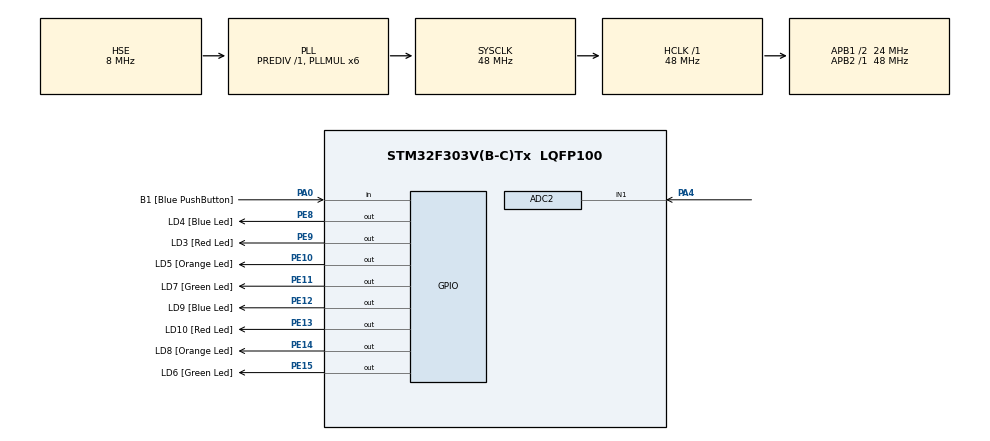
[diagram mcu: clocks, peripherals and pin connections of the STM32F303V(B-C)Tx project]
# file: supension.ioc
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ADC2.Channel-0\#ChannelRegularConversion=ADC_CHANNEL_1
ADC2.ContinuousConvMode=ENABLE
ADC2.DMAContinuousRequests=DISABLE
ADC2.InjNumberOfConversion=0
ADC2.NbrOfConversionFlag=1
ADC2.Offset-0\#ChannelRegularConversion=0
ADC2.OffsetNumber-0\#ChannelRegularConversion=ADC_OFFSET_NONE
ADC2.Rank-0\#ChannelRegularConversion=1
ADC2.SamplingTime-0\#ChannelRegularConversion=ADC_SAMPLETIME_1CYCLE_5
Dma.ADC2.0.Direction=DMA_PERIPH_TO_MEMORY
Dma.ADC2.0.Instance=DMA2_Channel1
Dma.ADC2.0.MemDataAlignment=DMA_MDATAALIGN_WORD
Dma.ADC2.0.MemInc=DMA_MINC_ENABLE
Dma.ADC2.0.Mode=DMA_CIRCULAR
Dma.ADC2.0.PeriphDataAlignment=DMA_PDATAALIGN_WORD
Dma.ADC2.0.PeriphInc=DMA_PINC_DISABLE
Dma.ADC2.0.Priority=DMA_PRIORITY_LOW
Dma.Request0=ADC2
Mcu.Family=STM32F3
Mcu.Name=STM32F303V(B-C)Tx
Mcu.Package=LQFP100
NVIC.DMA2_Channel1_IRQn=true\:0\:0\:false\:false\:true\:false\:true
NVIC.PriorityGroup=NVIC_PRIORITYGROUP_0
PA0.GPIO_Label=B1 [Blue PushButton]
PA0.Signal=GPIO_Input
PA4.Mode=IN1-Single-Ended
PA4.Signal=ADC2_IN1
PE10.GPIO_Label=LD5 [Orange Led]
PE10.Signal=GPIO_Output
PE11.GPIO_Label=LD7 [Green Led]
PE11.Signal=GPIO_Output
PE12.GPIO_Label=LD9 [Blue Led]
PE12.Signal=GPIO_Output
PE13.GPIO_Label=LD10 [Red Led]
PE13.Signal=GPIO_Output
PE14.GPIO_Label=LD8 [Orange Led]
PE14.Signal=GPIO_Output
PE15.GPIO_Label=LD6 [Green Led]
PE15.Signal=GPIO_Output
PE8.GPIO_Label=LD4 [Blue Led]
PE8.Signal=GPIO_Output
PE9.GPIO_Label=LD3 [Red Led]
PE9.Signal=GPIO_Output
PF0-OSC_IN.GPIO_Label=OSC_IN
PF0-OSC_IN.Mode=HSE-External-Oscillator
PF0-OSC_IN.Signal=RCC_OSC_IN
PF1-OSC_OUT.Mode=HSE-External-Oscillator
PF1-OSC_OUT.Signal=RCC_OSC_OUT
ProjectManager.HeapSize=0x200
ProjectManager.StackSize=0x400
ProjectManager.TargetToolchain=SW4STM32
RCC.AHBFreq_Value=48000000
RCC.APB1CLKDivider=RCC_HCLK_DIV2
RCC.APB1Freq_Value=24000000
RCC.APB1TimFreq_Value=48000000
RCC.APB2Freq_Value=48000000
RCC.APB2TimFreq_Value=48000000
RCC.CortexFreq_Value=48000000
RCC.HCLKFreq_Value=48000000
RCC.HSE_VALUE=8000000
RCC.HSI_VALUE=8000000
RCC.LSE_VALUE=32768
RCC.PLLMUL=RCC_PLL_MUL6
RCC.PLLSourceVirtual=RCC_PLLSOURCE_HSE
RCC.SYSCLKFreq_VALUE=48000000
RCC.SYSCLKSourceVirtual=RCC_SYSCLKSOURCE_PLLCLK
RCC.USBFreq_Value=48000000
board=STM32F3DISCOVERY

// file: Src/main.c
/* USER CODE BEGIN Header */
/**
  ******************************************************************************
  * @file           : main.c
  * @brief          : Main program body
  ******************************************************************************
  * @attention
  *
  * <h2><center>&copy; Copyright (c) 2019 STMicroelectronics.
  * All rights reserved.</center></h2>
  *
  * This software component is licensed by ST under BSD 3-Clause license,
  * the "License"; You may not use this file except in compliance with the
  * License. You may obtain a copy of the License at:
  *                        opensource.org/licenses/BSD-3-Clause
  *
  ******************************************************************************
  */
/* USER CODE END Header */

#include "main.h"
#include "adc.h"
#include "dma.h"
#include "gpio.h"

/* USER CODE BEGIN Includes */
#include <stdio.h>
/* USER CODE END Includes */

/* USER CODE BEGIN PTD */
volatile uint32_t acd_val;

double get_adc_flow() {
	return acd_val / (double) 4096.0;
}
/* USER CODE END PTD */

void SystemClock_Config(void);

int main(void)
{

  /* MCU Configuration--------------------------------------------------------*/

  /* Reset of all peripherals, Initializes the Flash interface and the Systick. */
  HAL_Init();

  /* Configure the system clock */
  SystemClock_Config();

  /* Initialize all configured peripherals */
  MX_GPIO_Init();
  MX_DMA_Init();
  MX_ADC2_Init();
  /* USER CODE BEGIN 2 */
  printf("OK!\n");
  HAL_ADC_Start_DMA(&hadc2, &acd_val, 1);
  /* USER CODE END 2 */

  /* Infinite loop */
  /* USER CODE BEGIN WHILE */
  while (1)
  {
	printf("%d\n", acd_val);
    HAL_GPIO_TogglePin(GPIOE, GPIO_PIN_9);
    HAL_Delay(500);
    /* USER CODE END WHILE */

  }
}

void SystemClock_Config(void)
{
  RCC_OscInitTypeDef RCC_OscInitStruct = {0};
  RCC_ClkInitTypeDef RCC_ClkInitStruct = {0};
  RCC_PeriphCLKInitTypeDef PeriphClkInit = {0};

  /** Initializes the CPU, AHB and APB busses clocks
  */
  RCC_OscInitStruct.OscillatorType = RCC_OSCILLATORTYPE_HSE;
  RCC_OscInitStruct.HSEState = RCC_HSE_ON;
  RCC_OscInitStruct.HSEPredivValue = RCC_HSE_PREDIV_DIV1;
  RCC_OscInitStruct.HSIState = RCC_HSI_ON;
  RCC_OscInitStruct.PLL.PLLState = RCC_PLL_ON;
  RCC_OscInitStruct.PLL.PLLSource = RCC_PLLSOURCE_HSE;
  RCC_OscInitStruct.PLL.PLLMUL = RCC_PLL_MUL6;
  if (HAL_RCC_OscConfig(&RCC_OscInitStruct) != HAL_OK)
  {
    Error_Handler();
  }
  /** Initializes the CPU, AHB and APB busses clocks
  */
  RCC_ClkInitStruct.ClockType = RCC_CLOCKTYPE_HCLK|RCC_CLOCKTYPE_SYSCLK
                              |RCC_CLOCKTYPE_PCLK1|RCC_CLOCKTYPE_PCLK2;
  RCC_ClkInitStruct.SYSCLKSource = RCC_SYSCLKSOURCE_PLLCLK;
  RCC_ClkInitStruct.AHBCLKDivider = RCC_SYSCLK_DIV1;
  RCC_ClkInitStruct.APB1CLKDivider = RCC_HCLK_DIV2;
  RCC_ClkInitStruct.APB2CLKDivider = RCC_HCLK_DIV1;

  if (HAL_RCC_ClockConfig(&RCC_ClkInitStruct, FLASH_LATENCY_1) != HAL_OK)
  {
    Error_Handler();
  }
  PeriphClkInit.PeriphClockSelection = RCC_PERIPHCLK_ADC12;
  PeriphClkInit.Adc12ClockSelection = RCC_ADC12PLLCLK_DIV1;
  if (HAL_RCCEx_PeriphCLKConfig(&PeriphClkInit) != HAL_OK)
  {
    Error_Handler();
  }
}

void Error_Handler(void)
{
}

/************************ (C) COPYRIGHT STMicroelectronics *****END OF FILE****/
